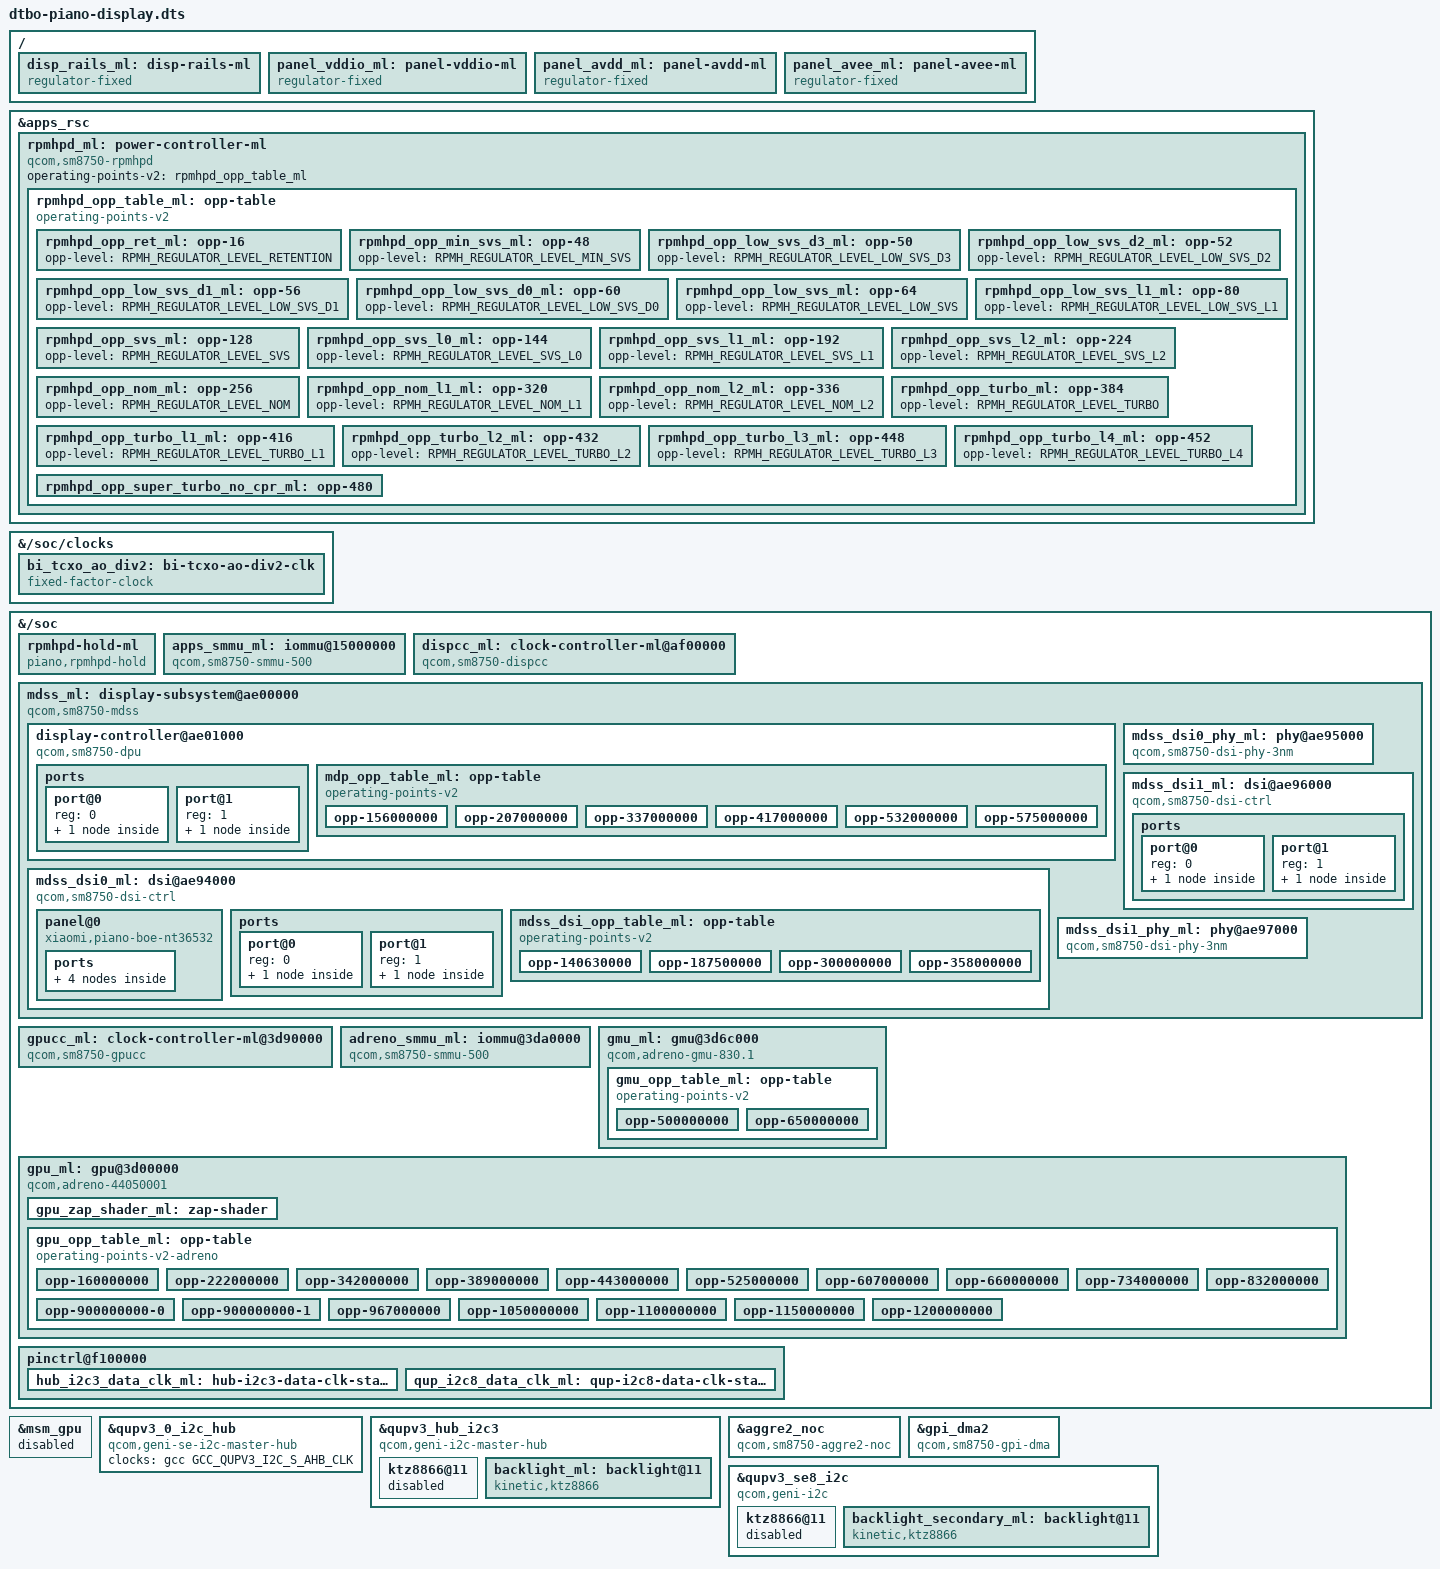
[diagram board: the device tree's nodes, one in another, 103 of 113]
// SPDX-License-Identifier: GPL-2.0-only
/*
 * Native display and GPU overlay, stacked on the GNOME/userdata overlay.
 *
 * Everything the native display and GPU need is added as NEW mainline nodes
 * next to the stock ones: the stock SMMU, dispcc, gpucc, DSI and KGSL nodes
 * keep their downstream compatibles and stay driverless.  In particular the
 * touch/Bluetooth DMA masters keep referencing the stock apps SMMU node, so
 * their verified pass-through routes cannot change whatever the order in
 * which modules load.  All drivers of the new nodes are modules that only
 * the ordered piano-display service loads (never coldplug).
 *
 * Register layout: upstream sm8750.dtsi (linux-next + the backported
 * "drm/msm: Support for Adreno 830 GPU" series), converted to the 1-cell
 * /soc bus of the stock base.  Board wiring: the stock piano DT
 * (piano-sde-display.dtsi, dsi-panel-p81-*.dtsi).
 *
 * Power: display and GPU rails were set up by the bootloader and must not
 * be switched by HLOS.
 *   - DSI/PHY and panel I/O rails (L3G, L1F/L3I, L12B) are fixed-regulator
 *     stand-ins: writing those RPMh resources during scanout corrupted the
 *     panel and reset the SoC in earlier rounds.
 *   - MMCX (dispcc, DPU, DSI) comes from a mainline rpmhpd instance.  Until
 *     its sync_state() rpmhpd clamps every domain that is used to its
 *     highest level and never votes anything down, which is exactly the
 *     safe behaviour on top of the bootloader votes.  rpmhpd_hold_ml is a
 *     consumer without a driver: with the default strict fw_devlink policy
 *     it keeps sync_state() (and with it every downvote of MMCX/CX/...)
 *     from ever happening.  Cost: MMCX and CX stay at their top level while
 *     the display is up.  Replace this once every rail consumer is
 *     described.
 *   - The GPU gets no rpmhpd domains: the GMU votes GX itself and its "gx"
 *     power domain (gxclkctl) is only used for recovery by the a8xx
 *     driver.  A GFX/GMXC vote from HLOS would be clamped to the maximum
 *     for good.
 *
 * Apps SMMU: a second, mainline node for the same SMMU, used only by the
 * MDSS.  The qcom SMMU driver adopts every stream match that is valid when
 * it probes as bypass, so it must load after /pianoinit has added the
 * matches of the running masters (piano-qup-smmu) and nothing may add
 * stream matches behind its back afterwards.  The MDSS stream (0x800/0x2)
 * reuses the bootloader match.
 *
 * Interconnects: the MDSS has no interconnect paths on purpose, the
 * mmss_noc provider is not bound and the bootloader's multimedia NoC votes
 * stay in place.
 */
#include "dtbo-piano-rootfs.dts"
#include <dt-bindings/clock/qcom,dsi-phy-28nm.h>
#include <dt-bindings/clock/qcom,rpmh.h>
#include <dt-bindings/clock/qcom,sm8750-dispcc.h>
#include <dt-bindings/clock/qcom,sm8750-gcc.h>
#include <dt-bindings/clock/qcom,sm8750-gpucc.h>
#include <dt-bindings/dma/qcom-gpi.h>
#include <dt-bindings/gpio/gpio.h>
#include <dt-bindings/interconnect/qcom,icc.h>
#include <dt-bindings/interconnect/qcom,sm8750-rpmh.h>
#include <dt-bindings/power/qcom,rpmhpd.h>

/ {
	/* mainline rpmhpd, a direct child of apps_rsc like rpmhcc_ml */
	fragment@260 {
		target = <&apps_rsc>;
		__overlay__ {
			rpmhpd_ml: power-controller-ml {
				compatible = "qcom,sm8750-rpmhpd";

				operating-points-v2 = <&rpmhpd_opp_table_ml>;

				#power-domain-cells = <1>;

				rpmhpd_opp_table_ml: opp-table {
					compatible = "operating-points-v2";

					rpmhpd_opp_ret_ml: opp-16 {
						opp-level = <RPMH_REGULATOR_LEVEL_RETENTION>;
					};

					rpmhpd_opp_min_svs_ml: opp-48 {
						opp-level = <RPMH_REGULATOR_LEVEL_MIN_SVS>;
					};

					rpmhpd_opp_low_svs_d3_ml: opp-50 {
						opp-level = <RPMH_REGULATOR_LEVEL_LOW_SVS_D3>;
					};

					rpmhpd_opp_low_svs_d2_ml: opp-52 {
						opp-level = <RPMH_REGULATOR_LEVEL_LOW_SVS_D2>;
					};

					rpmhpd_opp_low_svs_d1_ml: opp-56 {
						opp-level = <RPMH_REGULATOR_LEVEL_LOW_SVS_D1>;
					};

					rpmhpd_opp_low_svs_d0_ml: opp-60 {
						opp-level = <RPMH_REGULATOR_LEVEL_LOW_SVS_D0>;
					};

					rpmhpd_opp_low_svs_ml: opp-64 {
						opp-level = <RPMH_REGULATOR_LEVEL_LOW_SVS>;
					};

					rpmhpd_opp_low_svs_l1_ml: opp-80 {
						opp-level = <RPMH_REGULATOR_LEVEL_LOW_SVS_L1>;
					};

					rpmhpd_opp_svs_ml: opp-128 {
						opp-level = <RPMH_REGULATOR_LEVEL_SVS>;
					};

					rpmhpd_opp_svs_l0_ml: opp-144 {
						opp-level = <RPMH_REGULATOR_LEVEL_SVS_L0>;
					};

					rpmhpd_opp_svs_l1_ml: opp-192 {
						opp-level = <RPMH_REGULATOR_LEVEL_SVS_L1>;
					};

					rpmhpd_opp_svs_l2_ml: opp-224 {
						opp-level = <RPMH_REGULATOR_LEVEL_SVS_L2>;
					};

					rpmhpd_opp_nom_ml: opp-256 {
						opp-level = <RPMH_REGULATOR_LEVEL_NOM>;
					};

					rpmhpd_opp_nom_l1_ml: opp-320 {
						opp-level = <RPMH_REGULATOR_LEVEL_NOM_L1>;
					};

					rpmhpd_opp_nom_l2_ml: opp-336 {
						opp-level = <RPMH_REGULATOR_LEVEL_NOM_L2>;
					};

					rpmhpd_opp_turbo_ml: opp-384 {
						opp-level = <RPMH_REGULATOR_LEVEL_TURBO>;
					};

					rpmhpd_opp_turbo_l1_ml: opp-416 {
						opp-level = <RPMH_REGULATOR_LEVEL_TURBO_L1>;
					};

					rpmhpd_opp_turbo_l2_ml: opp-432 {
						opp-level = <RPMH_REGULATOR_LEVEL_TURBO_L2>;
					};

					rpmhpd_opp_turbo_l3_ml: opp-448 {
						opp-level = <RPMH_REGULATOR_LEVEL_TURBO_L3>;
					};

					rpmhpd_opp_turbo_l4_ml: opp-452 {
						opp-level = <RPMH_REGULATOR_LEVEL_TURBO_L4>;
					};

					rpmhpd_opp_super_turbo_no_cpr_ml: opp-480 {
						opp-level =
							<RPMH_REGULATOR_LEVEL_SUPER_TURBO_NO_CPR>;
					};
				};
			};
		};
	};

	fragment@261 {
		target-path = "/soc/clocks";
		__overlay__ {
			bi_tcxo_ao_div2: bi-tcxo-ao-div2-clk {
				compatible = "fixed-factor-clock";
				#clock-cells = <0>;
				clocks = <&rpmhcc_ml RPMH_CXO_CLK_A>;
				clock-mult = <1>;
				clock-div = <2>;
			};
		};
	};

	fragment@262 {
		target-path = "/";
		__overlay__ {
			/* Stand-ins for rails HLOS must never switch, see header */
			disp_rails_ml: disp-rails-ml {
				compatible = "regulator-fixed";
				regulator-name = "disp_rails_ml";
				regulator-always-on;
				regulator-boot-on;
			};

			panel_vddio_ml: panel-vddio-ml {
				compatible = "regulator-fixed";
				regulator-name = "panel_vddio_ml";
				regulator-min-microvolt = <1800000>;
				regulator-max-microvolt = <1800000>;
				regulator-always-on;
				regulator-boot-on;
			};

			/*
			 * LCD bias (+/-5.8 V from the KTZ8866 boost), enabled by
			 * TLMM 117/118: stock display_gpio_regulator_vsp/vsn.
			 * Kept on for now; DPMS switches only the panel.
			 */
			panel_avdd_ml: panel-avdd-ml {
				compatible = "regulator-fixed";
				regulator-name = "panel_avdd_ml";
				regulator-min-microvolt = <5800000>;
				regulator-max-microvolt = <5800000>;
				gpios = <&piano_tlmm_ml 117 GPIO_ACTIVE_HIGH>;
				enable-active-high;
				regulator-always-on;
				regulator-boot-on;
			};

			panel_avee_ml: panel-avee-ml {
				compatible = "regulator-fixed";
				regulator-name = "panel_avee_ml";
				regulator-min-microvolt = <5800000>;
				regulator-max-microvolt = <5800000>;
				gpios = <&piano_tlmm_ml 118 GPIO_ACTIVE_HIGH>;
				enable-active-high;
				startup-delay-us = <233>;
				regulator-always-on;
				regulator-boot-on;
			};
		};
	};

	fragment@263 {
		target-path = "/soc";
		__overlay__ {
			#address-cells = <1>;
			#size-cells = <1>;

			/* Never bound: blocks the rpmhpd sync_state(), see header */
			rpmhpd-hold-ml {
				compatible = "piano,rpmhpd-hold";
				power-domains = <&rpmhpd_ml RPMHPD_MMCX>,
						<&rpmhpd_ml RPMHPD_CX>;
			};

			apps_smmu_ml: iommu@15000000 {
				compatible = "qcom,sm8750-smmu-500", "qcom,smmu-500", "arm,mmu-500";
				reg = <0x15000000 0x100000>;
				#iommu-cells = <2>;
				#global-interrupts = <1>;
				/* same 113 lines as the stock node, in the same order */
				interrupts = <GIC_SPI 65 IRQ_TYPE_LEVEL_HIGH>,
						             <GIC_SPI 97 IRQ_TYPE_LEVEL_HIGH>,
						             <GIC_SPI 98 IRQ_TYPE_LEVEL_HIGH>,
						             <GIC_SPI 99 IRQ_TYPE_LEVEL_HIGH>,
						             <GIC_SPI 100 IRQ_TYPE_LEVEL_HIGH>,
						             <GIC_SPI 101 IRQ_TYPE_LEVEL_HIGH>,
						             <GIC_SPI 102 IRQ_TYPE_LEVEL_HIGH>,
						             <GIC_SPI 103 IRQ_TYPE_LEVEL_HIGH>,
						             <GIC_SPI 104 IRQ_TYPE_LEVEL_HIGH>,
						             <GIC_SPI 105 IRQ_TYPE_LEVEL_HIGH>,
						             <GIC_SPI 106 IRQ_TYPE_LEVEL_HIGH>,
						             <GIC_SPI 107 IRQ_TYPE_LEVEL_HIGH>,
						             <GIC_SPI 108 IRQ_TYPE_LEVEL_HIGH>,
						             <GIC_SPI 109 IRQ_TYPE_LEVEL_HIGH>,
						             <GIC_SPI 110 IRQ_TYPE_LEVEL_HIGH>,
						             <GIC_SPI 111 IRQ_TYPE_LEVEL_HIGH>,
						             <GIC_SPI 112 IRQ_TYPE_LEVEL_HIGH>,
						             <GIC_SPI 113 IRQ_TYPE_LEVEL_HIGH>,
						             <GIC_SPI 114 IRQ_TYPE_LEVEL_HIGH>,
						             <GIC_SPI 115 IRQ_TYPE_LEVEL_HIGH>,
						             <GIC_SPI 116 IRQ_TYPE_LEVEL_HIGH>,
						             <GIC_SPI 117 IRQ_TYPE_LEVEL_HIGH>,
						             <GIC_SPI 118 IRQ_TYPE_LEVEL_HIGH>,
						             <GIC_SPI 181 IRQ_TYPE_LEVEL_HIGH>,
						             <GIC_SPI 182 IRQ_TYPE_LEVEL_HIGH>,
						             <GIC_SPI 183 IRQ_TYPE_LEVEL_HIGH>,
						             <GIC_SPI 184 IRQ_TYPE_LEVEL_HIGH>,
						             <GIC_SPI 185 IRQ_TYPE_LEVEL_HIGH>,
						             <GIC_SPI 186 IRQ_TYPE_LEVEL_HIGH>,
						             <GIC_SPI 187 IRQ_TYPE_LEVEL_HIGH>,
						             <GIC_SPI 188 IRQ_TYPE_LEVEL_HIGH>,
						             <GIC_SPI 189 IRQ_TYPE_LEVEL_HIGH>,
						             <GIC_SPI 190 IRQ_TYPE_LEVEL_HIGH>,
						             <GIC_SPI 191 IRQ_TYPE_LEVEL_HIGH>,
						             <GIC_SPI 192 IRQ_TYPE_LEVEL_HIGH>,
						             <GIC_SPI 315 IRQ_TYPE_LEVEL_HIGH>,
						             <GIC_SPI 316 IRQ_TYPE_LEVEL_HIGH>,
						             <GIC_SPI 317 IRQ_TYPE_LEVEL_HIGH>,
						             <GIC_SPI 318 IRQ_TYPE_LEVEL_HIGH>,
						             <GIC_SPI 319 IRQ_TYPE_LEVEL_HIGH>,
						             <GIC_SPI 320 IRQ_TYPE_LEVEL_HIGH>,
						             <GIC_SPI 321 IRQ_TYPE_LEVEL_HIGH>,
						             <GIC_SPI 322 IRQ_TYPE_LEVEL_HIGH>,
						             <GIC_SPI 323 IRQ_TYPE_LEVEL_HIGH>,
						             <GIC_SPI 324 IRQ_TYPE_LEVEL_HIGH>,
						             <GIC_SPI 325 IRQ_TYPE_LEVEL_HIGH>,
						             <GIC_SPI 326 IRQ_TYPE_LEVEL_HIGH>,
						             <GIC_SPI 327 IRQ_TYPE_LEVEL_HIGH>,
						             <GIC_SPI 328 IRQ_TYPE_LEVEL_HIGH>,
						             <GIC_SPI 329 IRQ_TYPE_LEVEL_HIGH>,
						             <GIC_SPI 330 IRQ_TYPE_LEVEL_HIGH>,
						             <GIC_SPI 331 IRQ_TYPE_LEVEL_HIGH>,
						             <GIC_SPI 332 IRQ_TYPE_LEVEL_HIGH>,
						             <GIC_SPI 333 IRQ_TYPE_LEVEL_HIGH>,
						             <GIC_SPI 334 IRQ_TYPE_LEVEL_HIGH>,
						             <GIC_SPI 335 IRQ_TYPE_LEVEL_HIGH>,
						             <GIC_SPI 336 IRQ_TYPE_LEVEL_HIGH>,
						             <GIC_SPI 337 IRQ_TYPE_LEVEL_HIGH>,
						             <GIC_SPI 338 IRQ_TYPE_LEVEL_HIGH>,
						             <GIC_SPI 339 IRQ_TYPE_LEVEL_HIGH>,
						             <GIC_SPI 340 IRQ_TYPE_LEVEL_HIGH>,
						             <GIC_SPI 341 IRQ_TYPE_LEVEL_HIGH>,
						             <GIC_SPI 342 IRQ_TYPE_LEVEL_HIGH>,
						             <GIC_SPI 343 IRQ_TYPE_LEVEL_HIGH>,
						             <GIC_SPI 344 IRQ_TYPE_LEVEL_HIGH>,
						             <GIC_SPI 345 IRQ_TYPE_LEVEL_HIGH>,
						             <GIC_SPI 395 IRQ_TYPE_LEVEL_HIGH>,
						             <GIC_SPI 396 IRQ_TYPE_LEVEL_HIGH>,
						             <GIC_SPI 397 IRQ_TYPE_LEVEL_HIGH>,
						             <GIC_SPI 398 IRQ_TYPE_LEVEL_HIGH>,
						             <GIC_SPI 399 IRQ_TYPE_LEVEL_HIGH>,
						             <GIC_SPI 400 IRQ_TYPE_LEVEL_HIGH>,
						             <GIC_SPI 401 IRQ_TYPE_LEVEL_HIGH>,
						             <GIC_SPI 402 IRQ_TYPE_LEVEL_HIGH>,
						             <GIC_SPI 403 IRQ_TYPE_LEVEL_HIGH>,
						             <GIC_SPI 404 IRQ_TYPE_LEVEL_HIGH>,
						             <GIC_SPI 405 IRQ_TYPE_LEVEL_HIGH>,
						             <GIC_SPI 406 IRQ_TYPE_LEVEL_HIGH>,
						             <GIC_SPI 407 IRQ_TYPE_LEVEL_HIGH>,
						             <GIC_SPI 408 IRQ_TYPE_LEVEL_HIGH>,
						             <GIC_SPI 409 IRQ_TYPE_LEVEL_HIGH>,
						             <GIC_SPI 418 IRQ_TYPE_LEVEL_HIGH>,
						             <GIC_SPI 419 IRQ_TYPE_LEVEL_HIGH>,
						             <GIC_SPI 412 IRQ_TYPE_LEVEL_HIGH>,
						             <GIC_SPI 421 IRQ_TYPE_LEVEL_HIGH>,
						             <GIC_SPI 707 IRQ_TYPE_LEVEL_HIGH>,
						             <GIC_SPI 423 IRQ_TYPE_LEVEL_HIGH>,
						             <GIC_SPI 424 IRQ_TYPE_LEVEL_HIGH>,
						             <GIC_SPI 425 IRQ_TYPE_LEVEL_HIGH>,
						             <GIC_SPI 690 IRQ_TYPE_LEVEL_HIGH>,
						             <GIC_SPI 691 IRQ_TYPE_LEVEL_HIGH>,
						             <GIC_SPI 692 IRQ_TYPE_LEVEL_HIGH>,
						             <GIC_SPI 693 IRQ_TYPE_LEVEL_HIGH>,
						             <GIC_SPI 694 IRQ_TYPE_LEVEL_HIGH>,
						             <GIC_SPI 695 IRQ_TYPE_LEVEL_HIGH>,
						             <GIC_SPI 696 IRQ_TYPE_LEVEL_HIGH>,
						             <GIC_SPI 697 IRQ_TYPE_LEVEL_HIGH>,
						             <GIC_SPI 410 IRQ_TYPE_LEVEL_HIGH>,
						             <GIC_SPI 488 IRQ_TYPE_LEVEL_HIGH>,
						             <GIC_SPI 489 IRQ_TYPE_LEVEL_HIGH>,
						             <GIC_SPI 490 IRQ_TYPE_LEVEL_HIGH>,
						             <GIC_SPI 491 IRQ_TYPE_LEVEL_HIGH>,
						             <GIC_SPI 492 IRQ_TYPE_LEVEL_HIGH>,
						             <GIC_SPI 493 IRQ_TYPE_LEVEL_HIGH>,
						             <GIC_SPI 494 IRQ_TYPE_LEVEL_HIGH>,
						             <GIC_SPI 495 IRQ_TYPE_LEVEL_HIGH>,
						             <GIC_SPI 496 IRQ_TYPE_LEVEL_HIGH>,
						             <GIC_SPI 497 IRQ_TYPE_LEVEL_HIGH>,
						             <GIC_SPI 498 IRQ_TYPE_LEVEL_HIGH>,
						             <GIC_SPI 499 IRQ_TYPE_LEVEL_HIGH>,
						             <GIC_SPI 500 IRQ_TYPE_LEVEL_HIGH>,
						             <GIC_SPI 501 IRQ_TYPE_LEVEL_HIGH>,
						             <GIC_SPI 502 IRQ_TYPE_LEVEL_HIGH>;
				dma-coherent;
			};

			dispcc_ml: clock-controller-ml@af00000 {
				compatible = "qcom,sm8750-dispcc";
				reg = <0x0af00000 0x20000>;
				clocks = <&bi_tcxo_div2>,
					 <&bi_tcxo_ao_div2>,
					 <&gcc GCC_DISP_AHB_CLK>,
					 <&sleep_clk>,
					 <&mdss_dsi0_phy_ml DSI_BYTE_PLL_CLK>,
					 <&mdss_dsi0_phy_ml DSI_PIXEL_PLL_CLK>,
					 <&mdss_dsi1_phy_ml DSI_BYTE_PLL_CLK>,
					 <&mdss_dsi1_phy_ml DSI_PIXEL_PLL_CLK>,
					 <0>, <0>, /* dp0 */
					 <0>, <0>, /* dp1 */
					 <0>, <0>, /* dp2 */
					 <0>, <0>; /* dp3 */
				power-domains = <&rpmhpd_ml RPMHPD_MMCX>;
				required-opps = <&rpmhpd_opp_low_svs_ml>;
				#clock-cells = <1>;
				#reset-cells = <1>;
				#power-domain-cells = <1>;
			};

			mdss_ml: display-subsystem@ae00000 {
				compatible = "qcom,sm8750-mdss";
				reg = <0x0ae00000 0x1000>;
				reg-names = "mdss";
				interrupts = <GIC_SPI 83 IRQ_TYPE_LEVEL_HIGH>;
				clocks = <&dispcc_ml DISP_CC_MDSS_AHB_CLK>,
					 <&gcc GCC_DISP_HF_AXI_CLK>,
					 <&dispcc_ml DISP_CC_MDSS_MDP_CLK>;
				resets = <&dispcc_ml DISP_CC_MDSS_CORE_BCR>;
				power-domains = <&dispcc_ml MDSS_GDSC>;
				iommus = <&apps_smmu_ml 0x800 0x2>;
				interrupt-controller;
				#interrupt-cells = <1>;
				#address-cells = <1>;
				#size-cells = <1>;
				ranges;

				display-controller@ae01000 {
					compatible = "qcom,sm8750-dpu";
					reg = <0x0ae01000 0x93000>,
					      <0x0aeb0000 0x3000>;
					reg-names = "mdp", "vbif";
					interrupts-extended = <&mdss_ml 0>;
					clocks = <&gcc GCC_DISP_HF_AXI_CLK>,
						 <&dispcc_ml DISP_CC_MDSS_AHB_CLK>,
						 <&dispcc_ml DISP_CC_MDSS_MDP_LUT_CLK>,
						 <&dispcc_ml DISP_CC_MDSS_MDP_CLK>,
						 <&dispcc_ml DISP_CC_MDSS_VSYNC_CLK>;
					clock-names = "nrt_bus", "iface", "lut", "core", "vsync";
					assigned-clocks = <&dispcc_ml DISP_CC_MDSS_VSYNC_CLK>;
					assigned-clock-rates = <19200000>;
					operating-points-v2 = <&mdp_opp_table_ml>;
					power-domains = <&rpmhpd_ml RPMHPD_MMCX>;

					ports {
						#address-cells = <1>;
						#size-cells = <0>;

						port@0 {
							reg = <0>;
							dpu_intf1_out_ml: endpoint {
								remote-endpoint = <&mdss_dsi0_in_ml>;
							};
						};

						port@1 {
							reg = <1>;
							dpu_intf2_out_ml: endpoint {
								remote-endpoint = <&mdss_dsi1_in_ml>;
							};
						};
					};

					mdp_opp_table_ml: opp-table {
						compatible = "operating-points-v2";

						opp-156000000 {
							opp-hz = /bits/ 64 <156000000>;
							required-opps = <&rpmhpd_opp_low_svs_d1_ml>;
						};

						opp-207000000 {
							opp-hz = /bits/ 64 <207000000>;
							required-opps = <&rpmhpd_opp_low_svs_ml>;
						};

						opp-337000000 {
							opp-hz = /bits/ 64 <337000000>;
							required-opps = <&rpmhpd_opp_svs_ml>;
						};

						opp-417000000 {
							opp-hz = /bits/ 64 <417000000>;
							required-opps = <&rpmhpd_opp_svs_l1_ml>;
						};

						opp-532000000 {
							opp-hz = /bits/ 64 <532000000>;
							required-opps = <&rpmhpd_opp_nom_ml>;
						};

						opp-575000000 {
							opp-hz = /bits/ 64 <575000000>;
							required-opps = <&rpmhpd_opp_nom_l1_ml>;
						};
					};
				};

				/* DSI0 is the clock master of the bonded pair */
				mdss_dsi0_ml: dsi@ae94000 {
					compatible = "qcom,sm8750-dsi-ctrl", "qcom,mdss-dsi-ctrl";
					reg = <0x0ae94000 0x400>;
					reg-names = "dsi_ctrl";
					interrupts-extended = <&mdss_ml 4>;
					clocks = <&dispcc_ml DISP_CC_MDSS_BYTE0_CLK>,
						 <&dispcc_ml DISP_CC_MDSS_BYTE0_INTF_CLK>,
						 <&dispcc_ml DISP_CC_MDSS_PCLK0_CLK>,
						 <&dispcc_ml DISP_CC_MDSS_ESC0_CLK>,
						 <&dispcc_ml DISP_CC_MDSS_AHB_CLK>,
						 <&gcc GCC_DISP_HF_AXI_CLK>,
						 <&mdss_dsi0_phy_ml DSI_PIXEL_PLL_CLK>,
						 <&mdss_dsi0_phy_ml DSI_BYTE_PLL_CLK>,
						 <&dispcc_ml DISP_CC_ESYNC0_CLK>,
						 <&dispcc_ml DISP_CC_OSC_CLK>,
						 <&dispcc_ml DISP_CC_MDSS_BYTE0_CLK_SRC>,
						 <&dispcc_ml DISP_CC_MDSS_PCLK0_CLK_SRC>;
					clock-names = "byte", "byte_intf", "pixel", "core",
						      "iface", "bus", "dsi_pll_pixel",
						      "dsi_pll_byte", "esync", "osc",
						      "byte_src", "pixel_src";
					operating-points-v2 = <&mdss_dsi_opp_table_ml>;
					power-domains = <&rpmhpd_ml RPMHPD_MMCX>;
					phys = <&mdss_dsi0_phy_ml>;
					phy-names = "dsi";
					vdda-supply = <&disp_rails_ml>;

					qcom,dual-dsi-mode;
					qcom,sync-dual-dsi;
					qcom,master-dsi;

					#address-cells = <1>;
					#size-cells = <0>;

					panel@0 {
						/* touch lcd-id pin reads 1 = BOE ("p81 42 02 0a") */
						compatible = "xiaomi,piano-boe-nt36532", "novatek,nt36532";
						reg = <0>;
						reset-gpios = <&piano_tlmm_ml 98 GPIO_ACTIVE_LOW>;
						vddio-supply = <&panel_vddio_ml>;
						avdd-supply = <&panel_avdd_ml>;
						avee-supply = <&panel_avee_ml>;
						backlight = <&backlight_ml>;

						ports {
							#address-cells = <1>;
							#size-cells = <0>;

							port@0 {
								reg = <0>;
								panel_in_0_ml: endpoint {
									remote-endpoint = <&mdss_dsi0_out_ml>;
								};
							};

							port@1 {
								reg = <1>;
								panel_in_1_ml: endpoint {
									remote-endpoint = <&mdss_dsi1_out_ml>;
								};
							};
						};
					};

					ports {
						#address-cells = <1>;
						#size-cells = <0>;

						port@0 {
							reg = <0>;
							mdss_dsi0_in_ml: endpoint {
								remote-endpoint = <&dpu_intf1_out_ml>;
							};
						};

						port@1 {
							reg = <1>;
							mdss_dsi0_out_ml: endpoint {
								remote-endpoint = <&panel_in_0_ml>;
								data-lanes = <0 1 2 3>;
							};
						};
					};

					mdss_dsi_opp_table_ml: opp-table {
						compatible = "operating-points-v2";

						opp-140630000 {
							opp-hz = /bits/ 64 <140630000>;
							required-opps = <&rpmhpd_opp_low_svs_d1_ml>;
						};

						opp-187500000 {
							opp-hz = /bits/ 64 <187500000>;
							required-opps = <&rpmhpd_opp_low_svs_ml>;
						};

						opp-300000000 {
							opp-hz = /bits/ 64 <300000000>;
							required-opps = <&rpmhpd_opp_svs_ml>;
						};

						opp-358000000 {
							opp-hz = /bits/ 64 <358000000>;
							required-opps = <&rpmhpd_opp_svs_l1_ml>;
						};
					};
				};

				mdss_dsi0_phy_ml: phy@ae95000 {
					compatible = "qcom,sm8750-dsi-phy-3nm";
					reg = <0x0ae95000 0x200>,
					      <0x0ae95200 0x280>,
					      <0x0ae95500 0x400>;
					reg-names = "dsi_phy", "dsi_phy_lane", "dsi_pll";
					clocks = <&dispcc_ml DISP_CC_MDSS_AHB_CLK>,
						 <&bi_tcxo_div2>;
					clock-names = "iface", "ref";
					vdds-supply = <&disp_rails_ml>;
					#clock-cells = <1>;
					#phy-cells = <0>;
				};

				mdss_dsi1_ml: dsi@ae96000 {
					compatible = "qcom,sm8750-dsi-ctrl", "qcom,mdss-dsi-ctrl";
					reg = <0x0ae96000 0x400>;
					reg-names = "dsi_ctrl";
					interrupts-extended = <&mdss_ml 5>;
					clocks = <&dispcc_ml DISP_CC_MDSS_BYTE1_CLK>,
						 <&dispcc_ml DISP_CC_MDSS_BYTE1_INTF_CLK>,
						 <&dispcc_ml DISP_CC_MDSS_PCLK1_CLK>,
						 <&dispcc_ml DISP_CC_MDSS_ESC1_CLK>,
						 <&dispcc_ml DISP_CC_MDSS_AHB_CLK>,
						 <&gcc GCC_DISP_HF_AXI_CLK>,
						 <&mdss_dsi1_phy_ml DSI_PIXEL_PLL_CLK>,
						 <&mdss_dsi1_phy_ml DSI_BYTE_PLL_CLK>,
						 <&dispcc_ml DISP_CC_ESYNC1_CLK>,
						 <&dispcc_ml DISP_CC_OSC_CLK>,
						 <&dispcc_ml DISP_CC_MDSS_BYTE1_CLK_SRC>,
						 <&dispcc_ml DISP_CC_MDSS_PCLK1_CLK_SRC>;
					clock-names = "byte", "byte_intf", "pixel", "core",
						      "iface", "bus", "dsi_pll_pixel",
						      "dsi_pll_byte", "esync", "osc",
						      "byte_src", "pixel_src";
					/* DSI1 is the slave: take the DSI0 PLL */
					assigned-clocks = <&dispcc_ml DISP_CC_MDSS_BYTE1_CLK_SRC>,
							  <&dispcc_ml DISP_CC_MDSS_PCLK1_CLK_SRC>;
					assigned-clock-parents = <&mdss_dsi0_phy_ml DSI_BYTE_PLL_CLK>,
								 <&mdss_dsi0_phy_ml DSI_PIXEL_PLL_CLK>;
					operating-points-v2 = <&mdss_dsi_opp_table_ml>;
					power-domains = <&rpmhpd_ml RPMHPD_MMCX>;
					phys = <&mdss_dsi1_phy_ml>;
					phy-names = "dsi";
					vdda-supply = <&disp_rails_ml>;

					qcom,dual-dsi-mode;
					qcom,sync-dual-dsi;

					#address-cells = <1>;
					#size-cells = <0>;

					ports {
						#address-cells = <1>;
						#size-cells = <0>;

						port@0 {
							reg = <0>;
							mdss_dsi1_in_ml: endpoint {
								remote-endpoint = <&dpu_intf2_out_ml>;
							};
						};

						port@1 {
							reg = <1>;
							mdss_dsi1_out_ml: endpoint {
								remote-endpoint = <&panel_in_1_ml>;
								data-lanes = <0 1 2 3>;
							};
						};
					};
				};

				mdss_dsi1_phy_ml: phy@ae97000 {
					compatible = "qcom,sm8750-dsi-phy-3nm";
					reg = <0x0ae97000 0x200>,
					      <0x0ae97200 0x280>,
					      <0x0ae97500 0x400>;
					reg-names = "dsi_phy", "dsi_phy_lane", "dsi_pll";
					clocks = <&dispcc_ml DISP_CC_MDSS_AHB_CLK>,
						 <&bi_tcxo_div2>;
					clock-names = "iface", "ref";
					vdds-supply = <&disp_rails_ml>;
					#clock-cells = <1>;
					#phy-cells = <0>;
				};
			};

			gpucc_ml: clock-controller-ml@3d90000 {
				compatible = "qcom,sm8750-gpucc";
				reg = <0x03d90000 0x9800>;

				clocks = <&bi_tcxo_div2>,
					 <&gcc GCC_GPU_GPLL0_CLK_SRC>,
					 <&gcc GCC_GPU_GPLL0_DIV_CLK_SRC>;

				#clock-cells = <1>;
				#reset-cells = <1>;
				#power-domain-cells = <1>;
			};

			adreno_smmu_ml: iommu@3da0000 {
				compatible = "qcom,sm8750-smmu-500", "qcom,adreno-smmu",
					     "qcom,smmu-500", "arm,mmu-500";
				reg = <0x03da0000 0x40000>;
				#iommu-cells = <2>;
				#global-interrupts = <1>;
				interrupts = <GIC_SPI 674 IRQ_TYPE_LEVEL_HIGH>,
					     <GIC_SPI 678 IRQ_TYPE_LEVEL_HIGH>,
					     <GIC_SPI 679 IRQ_TYPE_LEVEL_HIGH>,
					     <GIC_SPI 680 IRQ_TYPE_LEVEL_HIGH>,
					     <GIC_SPI 681 IRQ_TYPE_LEVEL_HIGH>,
					     <GIC_SPI 682 IRQ_TYPE_LEVEL_HIGH>,
					     <GIC_SPI 683 IRQ_TYPE_LEVEL_HIGH>,
					     <GIC_SPI 684 IRQ_TYPE_LEVEL_HIGH>,
					     <GIC_SPI 685 IRQ_TYPE_LEVEL_HIGH>,
					     <GIC_SPI 686 IRQ_TYPE_LEVEL_HIGH>,
					     <GIC_SPI 687 IRQ_TYPE_LEVEL_HIGH>,
					     <GIC_SPI 688 IRQ_TYPE_LEVEL_HIGH>,
					     <GIC_SPI 422 IRQ_TYPE_LEVEL_HIGH>,
					     <GIC_SPI 476 IRQ_TYPE_LEVEL_HIGH>,
					     <GIC_SPI 574 IRQ_TYPE_LEVEL_HIGH>,
					     <GIC_SPI 575 IRQ_TYPE_LEVEL_HIGH>,
					     <GIC_SPI 576 IRQ_TYPE_LEVEL_HIGH>,
					     <GIC_SPI 577 IRQ_TYPE_LEVEL_HIGH>,
					     <GIC_SPI 660 IRQ_TYPE_LEVEL_HIGH>,
					     <GIC_SPI 662 IRQ_TYPE_LEVEL_HIGH>,
					     <GIC_SPI 665 IRQ_TYPE_LEVEL_HIGH>,
					     <GIC_SPI 666 IRQ_TYPE_LEVEL_HIGH>,
					     <GIC_SPI 667 IRQ_TYPE_LEVEL_HIGH>,
					     <GIC_SPI 669 IRQ_TYPE_LEVEL_HIGH>,
					     <GIC_SPI 670 IRQ_TYPE_LEVEL_HIGH>,
					     <GIC_SPI 700 IRQ_TYPE_LEVEL_HIGH>;
				clocks = <&gpucc_ml GPU_CC_HLOS1_VOTE_GPU_SMMU_CLK>;
				clock-names = "hlos";
				power-domains = <&gpucc_ml GPU_CC_CX_GDSC>;
				dma-coherent;
			};

			gmu_ml: gmu@3d6c000 {
				compatible = "qcom,adreno-gmu-830.1", "qcom,adreno-gmu";

				reg = <0x03d6c000 0x32000>;
				reg-names = "gmu";

				interrupts = <GIC_SPI 304 IRQ_TYPE_LEVEL_HIGH>,
					     <GIC_SPI 305 IRQ_TYPE_LEVEL_HIGH>;
				interrupt-names = "hfi", "gmu";

				clocks = <&gpucc_ml GPU_CC_AHB_CLK>,
					 <&gpucc_ml GPU_CC_CX_GMU_CLK>,
					 <&gpucc_ml GPU_CC_CXO_CLK>,
					 <&gcc GCC_DDRSS_GPU_AXI_CLK>,
					 <&gcc GCC_GPU_GEMNOC_GFX_CLK>,
					 <&gpucc_ml GPU_CC_HUB_CX_INT_CLK>;
				clock-names = "ahb",
					      "gmu",
					      "cxo",
					      "axi",
					      "memnoc",
					      "hub";

				/* no "gx": the GMU firmware owns the GX GDSC, see header */
				power-domains = <&gpucc_ml GPU_CC_CX_GDSC>;
				power-domain-names = "cx";

				iommus = <&adreno_smmu_ml 5 0x0>;

				qcom,qmp = <&aoss_qmp>;

				operating-points-v2 = <&gmu_opp_table_ml>;

				gmu_opp_table_ml: opp-table {
					compatible = "operating-points-v2";

					opp-500000000 {
						opp-hz = /bits/ 64 <500000000>;
						opp-level = <RPMH_REGULATOR_LEVEL_LOW_SVS>;
					};

					opp-650000000 {
						opp-hz = /bits/ 64 <650000000>;
						opp-level = <RPMH_REGULATOR_LEVEL_SVS>;
					};
				};
			};

			gpu_ml: gpu@3d00000 {
				compatible = "qcom,adreno-44050001", "qcom,adreno";
				reg = <0x03d00000 0x6d000>,
				      <0x03d9e000 0x2000>;
				reg-names = "kgsl_3d0_reg_memory",
					    "cx_mem";

				interrupts = <GIC_SPI 300 IRQ_TYPE_LEVEL_HIGH>;

				iommus = <&adreno_smmu_ml 0 0x0>,
					 <&adreno_smmu_ml 1 0x0>;

				operating-points-v2 = <&gpu_opp_table_ml>;

				qcom,gmu = <&gmu_ml>;

				nvmem-cells = <&gpu_speed_bin>;
				nvmem-cell-names = "speed_bin";

				interconnects = <&gem_noc MASTER_GFX3D QCOM_ICC_TAG_ALWAYS
						 &mc_virt SLAVE_EBI1 QCOM_ICC_TAG_ALWAYS>;
				interconnect-names = "gfx-mem";


				gpu_zap_shader_ml: zap-shader {
					memory-region = <&gpu_microcode_mem>;
					/* Xiaomi-signed, from the odm partition */
					firmware-name = "qcom/sm8750/xiaomi/piano/gen80000_zap.mbn";
				};

				gpu_opp_table_ml: opp-table {
					compatible = "operating-points-v2-adreno",
						     "operating-points-v2";

					opp-160000000 {
						opp-hz = /bits/ 64 <160000000>;
						opp-level = <RPMH_REGULATOR_LEVEL_LOW_SVS_D3>;
						opp-peak-kBps = <2136718>;
						opp-supported-hw = <0x1f>;
					};

					opp-222000000 {
						opp-hz = /bits/ 64 <222000000>;
						opp-level = <RPMH_REGULATOR_LEVEL_LOW_SVS_D2>;
						opp-peak-kBps = <2136718>;
						opp-supported-hw = <0x1f>;
					};

					opp-342000000 {
						opp-hz = /bits/ 64 <342000000>;
						opp-level = <RPMH_REGULATOR_LEVEL_LOW_SVS_D1>;
						opp-peak-kBps = <5285156>;
						opp-supported-hw = <0x1f>;
					};

					opp-389000000 {
						opp-hz = /bits/ 64 <389000000>;
						opp-level = <RPMH_REGULATOR_LEVEL_LOW_SVS_D0>;
						opp-peak-kBps = <6074218>;
						qcom,opp-acd-level = <0xc8285ffd>;
						opp-supported-hw = <0x1f>;
					};

					opp-443000000 {
						opp-hz = /bits/ 64 <443000000>;
						opp-level = <RPMH_REGULATOR_LEVEL_LOW_SVS>;
						opp-peak-kBps = <6074218>;
						qcom,opp-acd-level = <0xc02e5ffd>;
						opp-supported-hw = <0x1f>;
					};

					opp-525000000 {
						opp-hz = /bits/ 64 <525000000>;
						opp-level = <RPMH_REGULATOR_LEVEL_LOW_SVS_L1>;
						opp-peak-kBps = <6074218>;
						qcom,opp-acd-level = <0xc02e5ffd>;
						opp-supported-hw = <0x1f>;
					};

					opp-607000000 {
						opp-hz = /bits/ 64 <607000000>;
						opp-level = <RPMH_REGULATOR_LEVEL_SVS>;
						opp-peak-kBps = <8171875>;
						qcom,opp-acd-level = <0xa82e5ffd>;
						opp-supported-hw = <0x1f>;
					};

					opp-660000000 {
						opp-hz = /bits/ 64 <660000000>;
						opp-level = <RPMH_REGULATOR_LEVEL_SVS_L0>;
						opp-peak-kBps = <8171875>;
						qcom,opp-acd-level = <0x882c5ffd>;
						opp-supported-hw = <0x1f>;
					};

					opp-734000000 {
						opp-hz = /bits/ 64 <734000000>;
						opp-level = <RPMH_REGULATOR_LEVEL_SVS_L1>;
						opp-peak-kBps = <12449218>;
						qcom,opp-acd-level = <0xa82a5ffd>;
						opp-supported-hw = <0x1f>;
					};

					opp-832000000 {
						opp-hz = /bits/ 64 <832000000>;
						opp-level = <RPMH_REGULATOR_LEVEL_SVS_L2>;
						opp-peak-kBps = <16500000>;
						qcom,opp-acd-level = <0x882a5ffd>;
						opp-supported-hw = <0x1f>;
					};

					opp-900000000-0 {
						opp-hz = /bits/ 64 <900000000>;
						opp-level = <RPMH_REGULATOR_LEVEL_NOM>;
						opp-peak-kBps = <16500000>;
						qcom,opp-acd-level = <0x882a5ffd>;
						opp-supported-hw = <0x0f>;
					};

					/* Only applicable for SKUs which has 900Mhz as Fmax */
					opp-900000000-1 {
						opp-hz = /bits/ 64 <900000000>;
						opp-level = <RPMH_REGULATOR_LEVEL_NOM>;
						opp-peak-kBps = <18597656>;
						qcom,opp-acd-level = <0x882a5ffd>;
						opp-supported-hw = <0x10>;
					};

					opp-967000000 {
						opp-hz = /bits/ 64 <967000000>;
						opp-level = <RPMH_REGULATOR_LEVEL_NOM_L1>;
						opp-peak-kBps = <18597656>;
						qcom,opp-acd-level = <0x882a5ffd>;
						opp-supported-hw = <0x0f>;
					};

					opp-1050000000 {
						opp-hz = /bits/ 64 <1050000000>;
						opp-level = <RPMH_REGULATOR_LEVEL_TURBO_L1>;
						opp-peak-kBps = <18597656>;
						qcom,opp-acd-level = <0xa8295ffd>;
						opp-supported-hw = <0x0f>;
					};

					opp-1100000000 {
						opp-hz = /bits/ 64 <1100000000>;
						opp-level = <RPMH_REGULATOR_LEVEL_TURBO_L3>;
						opp-peak-kBps = <18597656>;
						qcom,opp-acd-level = <0x88295ffd>;
						opp-supported-hw = <0x05>;
					};

					opp-1150000000 {
						opp-hz = /bits/ 64 <1150000000>;
						opp-level = <RPMH_REGULATOR_LEVEL_TURBO_L3>;
						opp-peak-kBps = <18597656>;
						qcom,opp-acd-level = <0x88295ffd>;
						opp-supported-hw = <0x02>;
					};

					opp-1200000000 {
						opp-hz = /bits/ 64 <1200000000>;
						opp-level = <RPMH_REGULATOR_LEVEL_TURBO_L4>;
						opp-peak-kBps = <18597656>;
						qcom,opp-acd-level = <0x88295ffd>;
						opp-supported-hw = <0x01>;
					};
				};
			};
		};
	};

	/* GPU: the stock KGSL node has no driver; keep it visibly out of the way */
	fragment@264 {
		target = <&msm_gpu>;
		__overlay__ {
			status = "disabled";
		};
	};

	/*
	 * Board pin states on the mainline TLMM node. The bootloader skips
	 * fragments that target a node created by this overlay, so merge by
	 * path instead of target = <&piano_tlmm_ml>.
	 */
	fragment@265 {
		target-path = "/soc";
		__overlay__ {
			pinctrl@f100000 {
				/* stock qupv3_hub_i2c3_*_active */
				hub_i2c3_data_clk_ml: hub-i2c3-data-clk-state {
					pins = "gpio70", "gpio71";
					function = "i2chub0_se3";
					drive-strength = <2>;
					bias-pull-up;
				};

				/* stock qupv3_se8_i2c_*_active */
				qup_i2c8_data_clk_ml: qup-i2c8-data-clk-state {
					pins = "gpio0", "gpio1";
					function = "qup2_se0";
					drive-strength = <2>;
					bias-pull-up;
				};
			};
		};
	};

	/*
	 * Backlight: two KTZ8866, both at 0x11, one on I2C hub SE3 (HWEN =
	 * TLMM 2, stock ktz8866,id 0) and one on QUP2 SE8 (id 1).  The
	 * downstream driver always programs both identically; the probe of
	 * the stock driver writes nothing, the bootloader configured them.
	 *
	 * I2C hub wrapper: mainline master-hub binding on the stock node.
	 */
	fragment@266 {
		target = <&qupv3_0_i2c_hub>;
		__overlay__ {
			compatible = "qcom,geni-se-i2c-master-hub";
			clocks = <&gcc GCC_QUPV3_I2C_S_AHB_CLK>;
			clock-names = "s-ahb";
		};
	};

	fragment@267 {
		target = <&qupv3_hub_i2c3>;
		__overlay__ {
			compatible = "qcom,geni-i2c-master-hub";
			clocks = <&gcc GCC_QUPV3_I2C_S3_CLK>,
				 <&gcc GCC_QUPV3_I2C_CORE_CLK>;
			clock-names = "se", "core";
			interconnects = <&clk_virt MASTER_QUP_CORE_0 QCOM_ICC_TAG_ALWAYS
					 &clk_virt SLAVE_QUP_CORE_0 QCOM_ICC_TAG_ALWAYS>,
					<&gem_noc MASTER_APPSS_PROC QCOM_ICC_TAG_ALWAYS
					 &config_noc SLAVE_I2C QCOM_ICC_TAG_ALWAYS>;
			interconnect-names = "qup-core", "qup-config";
			pinctrl-names = "default";
			pinctrl-0 = <&hub_i2c3_data_clk_ml>;
			/* The stock "sleep" state is in the driverless stock TLMM. */
			pinctrl-1 = <&hub_i2c3_data_clk_ml>;
			clock-frequency = <400000>;

			ktz8866@11 {
				status = "disabled";
			};

			backlight_ml: backlight@11 {
				compatible = "kinetic,ktz8866";
				reg = <0x11>;
				vddpos-supply = <&panel_avdd_ml>;
				vddneg-supply = <&panel_avee_ml>;
				enable-gpios = <&piano_tlmm_ml 2 GPIO_ACTIVE_HIGH>;
				/* downstream enable value 0x7f: all six sinks */
				current-num-sinks = <6>;
				kinetic,secondary-backlight = <&backlight_secondary_ml>;
			};
		};
	};

	/* QUP2 memory path of SE8 */
	fragment@270 {
		target = <&aggre2_noc>;
		__overlay__ {
			compatible = "qcom,sm8750-aggre2-noc";
			#interconnect-cells = <2>;
			qcom,bcm-voter-names = "hlos";
			qcom,bcm-voters = <&apps_bcm_voter_ml>;
		};
	};

	/* QUP2 GPI DMA, same treatment as QUP1 in the touch overlay */
	fragment@268 {
		target = <&gpi_dma2>;
		__overlay__ {
			compatible = "qcom,sm8750-gpi-dma", "qcom,sm6350-gpi-dma";
			dma-channels = <12>;
			dma-channel-mask = <0x1e>;
			#dma-cells = <3>;
		};
	};

	fragment@269 {
		target = <&qupv3_se8_i2c>;
		__overlay__ {
			compatible = "qcom,geni-i2c";
			clocks = <&gcc GCC_QUPV3_WRAP2_S0_CLK>;
			clock-names = "se";
			interconnects = <&clk_virt MASTER_QUP_CORE_2 QCOM_ICC_TAG_ALWAYS
					 &clk_virt SLAVE_QUP_CORE_2 QCOM_ICC_TAG_ALWAYS>,
					<&gem_noc MASTER_APPSS_PROC QCOM_ICC_TAG_ALWAYS
					 &config_noc SLAVE_QUP_2 QCOM_ICC_TAG_ALWAYS>,
					<&aggre2_noc MASTER_QUP_2 QCOM_ICC_TAG_ALWAYS
					 &mc_virt SLAVE_EBI1 QCOM_ICC_TAG_ALWAYS>;
			interconnect-names = "qup-core", "qup-config", "qup-memory";
			dmas = <&gpi_dma2 0 0 QCOM_GPI_I2C>,
			       <&gpi_dma2 1 0 QCOM_GPI_I2C>;
			dma-names = "tx", "rx";
			pinctrl-names = "default";
			pinctrl-0 = <&qup_i2c8_data_clk_ml>;
			/* The stock "sleep" state is in the driverless stock TLMM. */
			pinctrl-1 = <&qup_i2c8_data_clk_ml>;
			clock-frequency = <400000>;

			ktz8866@11 {
				status = "disabled";
			};

			backlight_secondary_ml: backlight@11 {
				compatible = "kinetic,ktz8866";
				reg = <0x11>;
				kinetic,secondary;
			};
		};
	};
};
